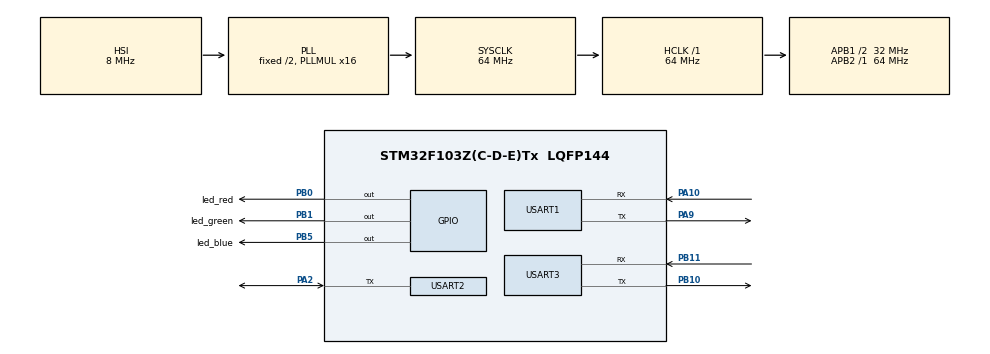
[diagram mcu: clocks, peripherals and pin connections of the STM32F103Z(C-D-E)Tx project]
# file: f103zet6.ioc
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Dma.Request0=USART1_TX
Dma.Request1=USART1_RX
Dma.Request2=USART3_RX
Dma.Request3=USART3_TX
Dma.USART1_RX.1.Direction=DMA_PERIPH_TO_MEMORY
Dma.USART1_RX.1.Instance=DMA1_Channel5
Dma.USART1_RX.1.MemDataAlignment=DMA_MDATAALIGN_BYTE
Dma.USART1_RX.1.MemInc=DMA_MINC_ENABLE
Dma.USART1_RX.1.Mode=DMA_NORMAL
Dma.USART1_RX.1.PeriphDataAlignment=DMA_PDATAALIGN_BYTE
Dma.USART1_RX.1.PeriphInc=DMA_PINC_DISABLE
Dma.USART1_RX.1.Priority=DMA_PRIORITY_LOW
Dma.USART1_TX.0.Direction=DMA_MEMORY_TO_PERIPH
Dma.USART1_TX.0.Instance=DMA1_Channel4
Dma.USART1_TX.0.MemDataAlignment=DMA_MDATAALIGN_BYTE
Dma.USART1_TX.0.MemInc=DMA_MINC_ENABLE
Dma.USART1_TX.0.Mode=DMA_NORMAL
Dma.USART1_TX.0.PeriphDataAlignment=DMA_PDATAALIGN_BYTE
Dma.USART1_TX.0.PeriphInc=DMA_PINC_DISABLE
Dma.USART1_TX.0.Priority=DMA_PRIORITY_LOW
Dma.USART3_RX.2.Direction=DMA_PERIPH_TO_MEMORY
Dma.USART3_RX.2.Instance=DMA1_Channel3
Dma.USART3_RX.2.MemDataAlignment=DMA_MDATAALIGN_BYTE
Dma.USART3_RX.2.MemInc=DMA_MINC_ENABLE
Dma.USART3_RX.2.Mode=DMA_NORMAL
Dma.USART3_RX.2.PeriphDataAlignment=DMA_PDATAALIGN_BYTE
Dma.USART3_RX.2.PeriphInc=DMA_PINC_DISABLE
Dma.USART3_RX.2.Priority=DMA_PRIORITY_LOW
Dma.USART3_TX.3.Direction=DMA_MEMORY_TO_PERIPH
Dma.USART3_TX.3.Instance=DMA1_Channel2
Dma.USART3_TX.3.MemDataAlignment=DMA_MDATAALIGN_BYTE
Dma.USART3_TX.3.MemInc=DMA_MINC_ENABLE
Dma.USART3_TX.3.Mode=DMA_NORMAL
Dma.USART3_TX.3.PeriphDataAlignment=DMA_PDATAALIGN_BYTE
Dma.USART3_TX.3.PeriphInc=DMA_PINC_DISABLE
Dma.USART3_TX.3.Priority=DMA_PRIORITY_LOW
FREERTOS.Tasks01=defaultTask,24,512,StartDefaultTask,Default,NULL,Dynamic,NULL,NULL
FREERTOS.configCHECK_FOR_STACK_OVERFLOW=0
FREERTOS.configTOTAL_HEAP_SIZE=24576
Mcu.Family=STM32F1
Mcu.Name=STM32F103Z(C-D-E)Tx
Mcu.Package=LQFP144
NVIC.DMA1_Channel2_IRQn=true\:5\:0\:false\:false\:true\:true\:false\:true\:true
NVIC.DMA1_Channel3_IRQn=true\:5\:0\:false\:false\:true\:true\:false\:true\:true
NVIC.DMA1_Channel4_IRQn=true\:5\:0\:false\:false\:true\:true\:false\:true\:true
NVIC.DMA1_Channel5_IRQn=true\:5\:0\:false\:false\:true\:true\:false\:true\:true
NVIC.PriorityGroup=NVIC_PRIORITYGROUP_4
NVIC.TIM1_UP_IRQn=true\:15\:0\:false\:false\:true\:false\:false\:true\:true
NVIC.TIM2_IRQn=true\:5\:0\:false\:false\:true\:true\:true\:true\:true
NVIC.TimeBase=TIM1_UP_IRQn
NVIC.TimeBaseIP=TIM1
NVIC.USART1_IRQn=true\:5\:0\:false\:false\:true\:true\:true\:true\:true
NVIC.USART2_IRQn=true\:5\:0\:false\:false\:true\:true\:true\:true\:true
NVIC.USART3_IRQn=true\:5\:0\:false\:false\:true\:true\:true\:true\:true
PA10.Mode=Asynchronous
PA10.Signal=USART1_RX
PA13.Mode=JTAG_4_pins
PA13.Signal=SYS_JTMS-SWDIO
PA14.Mode=JTAG_4_pins
PA14.Signal=SYS_JTCK-SWCLK
PA15.Mode=JTAG_4_pins
PA15.Signal=SYS_JTDI
PA2.Mode=Half_duplex(single_wire_mode)
PA2.Signal=USART2_TX
PA9.Mode=Asynchronous
PA9.Signal=USART1_TX
PB0.GPIO_Label=led_red
PB0.Signal=GPIO_Output
PB1.GPIO_Label=led_green
PB1.Signal=GPIO_Output
PB10.Mode=Asynchronous
PB10.Signal=USART3_TX
PB11.Mode=Asynchronous
PB11.Signal=USART3_RX
PB3.Mode=JTAG_4_pins
PB3.Signal=SYS_JTDO-TRACESWO
PB5.GPIO_Label=led_blue
PB5.Signal=GPIO_Output
ProjectManager.HeapSize=0x800
ProjectManager.StackSize=0x400
ProjectManager.TargetToolchain=CMake
RCC.AHBFreq_Value=64000000
RCC.APB1CLKDivider=RCC_HCLK_DIV2
RCC.APB1Freq_Value=32000000
RCC.APB1TimFreq_Value=64000000
RCC.APB2Freq_Value=64000000
RCC.APB2TimFreq_Value=64000000
RCC.HCLKFreq_Value=64000000
RCC.PLLMUL=RCC_PLL_MUL16
RCC.SYSCLKFreq_VALUE=64000000
RCC.SYSCLKSource=RCC_SYSCLKSOURCE_PLLCLK
RCC.USBFreq_Value=64000000
TIM2.AutoReloadPreload=TIM_AUTORELOAD_PRELOAD_ENABLE
TIM2.Period=1000
TIM2.Prescaler=64
USART1.VirtualMode=VM_ASYNC
USART2.VirtualMode=VM_ASYNC
USART3.VirtualMode=VM_ASYNC
VP_FREERTOS_VS_CMSIS_V2.Mode=CMSIS_V2
VP_SYS_VS_tim1.Mode=TIM1
VP_TIM2_VS_ClockSourceINT.Mode=Internal
board=custom

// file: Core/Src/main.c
/* USER CODE BEGIN Header */
/**
 ******************************************************************************
 * @file           : main.c
 * @brief          : Main program body
 ******************************************************************************
 * @attention
 *
 * Copyright (c) 2025 STMicroelectronics.
 * All rights reserved.
 *
 * This software is licensed under terms that can be found in the LICENSE file
 * in the root directory of this software component.
 * If no LICENSE file comes with this software, it is provided AS-IS.
 *
 ******************************************************************************
 */
/* USER CODE END Header */
#include "main.h"
#include "cmsis_os.h"
#include "dma.h"
#include "tim.h"
#include "usart.h"
#include "gpio.h"

/* USER CODE BEGIN Includes */
#include "string.h"
/* USER CODE END Includes */

void SystemClock_Config(void);
void MX_FREERTOS_Init(void);
/* USER CODE BEGIN PFP */
int _write(int file, char *ptr, int len)
{
  (void)file; // Suppress unused parameter warning
  HAL_UART_Transmit(&huart1, (uint8_t *)ptr, len, HAL_MAX_DELAY);
  return len;
}

/* USER CODE END PFP */

/* USER CODE BEGIN 0 */

int motor_cmd(const char *str)
{
  HAL_StatusTypeDef ret;
  ret = HAL_UART_Transmit(&huart2, (uint8_t *)str, strlen((char *)str), 0xFFFF);

  return ret;
}
/* USER CODE END 0 */

int main(void)
{

  /* MCU Configuration--------------------------------------------------------*/

  /* Reset of all peripherals, Initializes the Flash interface and the Systick. */
  HAL_Init();

  /* Configure the system clock */
  SystemClock_Config();

  /* Initialize all configured peripherals */
  MX_GPIO_Init();
  MX_DMA_Init();
  MX_USART1_UART_Init();
  MX_USART2_UART_Init();
  MX_TIM2_Init();
  MX_USART3_UART_Init();

  /* Init scheduler */
  osKernelInitialize();

  /* Call init function for freertos objects (in cmsis_os2.c) */
  MX_FREERTOS_Init();

  /* Start scheduler */
  osKernelStart();

  /* We should never get here as control is now taken by the scheduler */

  /* Infinite loop */
  while (1)
  {

  }
}

void SystemClock_Config(void)
{
  RCC_OscInitTypeDef RCC_OscInitStruct = {0};
  RCC_ClkInitTypeDef RCC_ClkInitStruct = {0};

  /** Initializes the RCC Oscillators according to the specified parameters
   * in the RCC_OscInitTypeDef structure.
   */
  RCC_OscInitStruct.OscillatorType = RCC_OSCILLATORTYPE_HSI;
  RCC_OscInitStruct.HSIState = RCC_HSI_ON;
  RCC_OscInitStruct.HSICalibrationValue = RCC_HSICALIBRATION_DEFAULT;
  RCC_OscInitStruct.PLL.PLLState = RCC_PLL_ON;
  RCC_OscInitStruct.PLL.PLLSource = RCC_PLLSOURCE_HSI_DIV2;
  RCC_OscInitStruct.PLL.PLLMUL = RCC_PLL_MUL16;
  if (HAL_RCC_OscConfig(&RCC_OscInitStruct) != HAL_OK)
  {
    Error_Handler();
  }

  /** Initializes the CPU, AHB and APB buses clocks
   */
  RCC_ClkInitStruct.ClockType = RCC_CLOCKTYPE_HCLK | RCC_CLOCKTYPE_SYSCLK | RCC_CLOCKTYPE_PCLK1 | RCC_CLOCKTYPE_PCLK2;
  RCC_ClkInitStruct.SYSCLKSource = RCC_SYSCLKSOURCE_PLLCLK;
  RCC_ClkInitStruct.AHBCLKDivider = RCC_SYSCLK_DIV1;
  RCC_ClkInitStruct.APB1CLKDivider = RCC_HCLK_DIV2;
  RCC_ClkInitStruct.APB2CLKDivider = RCC_HCLK_DIV1;

  if (HAL_RCC_ClockConfig(&RCC_ClkInitStruct, FLASH_LATENCY_2) != HAL_OK)
  {
    Error_Handler();
  }
}

void HAL_TIM_PeriodElapsedCallback(TIM_HandleTypeDef *htim)
{
  if (htim->Instance == TIM1)
  {
    HAL_IncTick();
  }
}

void Error_Handler(void)
{
  __disable_irq();
  while (1)
  {
  }
}

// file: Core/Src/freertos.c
/* USER CODE BEGIN Header */
/**
 ******************************************************************************
 * File Name          : freertos.c
 * Description        : Code for freertos applications
 ******************************************************************************
 * @attention
 *
 * Copyright (c) 2025 STMicroelectronics.
 * All rights reserved.
 *
 * This software is licensed under terms that can be found in the LICENSE file
 * in the root directory of this software component.
 * If no LICENSE file comes with this software, it is provided AS-IS.
 *
 ******************************************************************************
 */
/* USER CODE END Header */

#include "FreeRTOS.h"
#include "task.h"
#include "main.h"
#include "cmsis_os.h"

/* Definitions for defaultTask */
osThreadId_t defaultTaskHandle;
const osThreadAttr_t defaultTask_attributes = {
  .name = "defaultTask",
  .stack_size = 512 * 4,
  .priority = (osPriority_t) osPriorityNormal,
};

void StartDefaultTask(void *argument);

void MX_FREERTOS_Init(void); /* (MISRA C 2004 rule 8.1) */

void MX_FREERTOS_Init(void) {

  /* Create the thread(s) */
  /* creation of defaultTask */
  defaultTaskHandle = osThreadNew(StartDefaultTask, NULL, &defaultTask_attributes);

}

void StartDefaultTask(void *argument)
{
  /* USER CODE BEGIN StartDefaultTask */
  extern int app_main(void);
  /* Infinite loop */
  app_main();
  for (;;)
  {
    osDelay(1);
  }
  /* USER CODE END StartDefaultTask */
}
